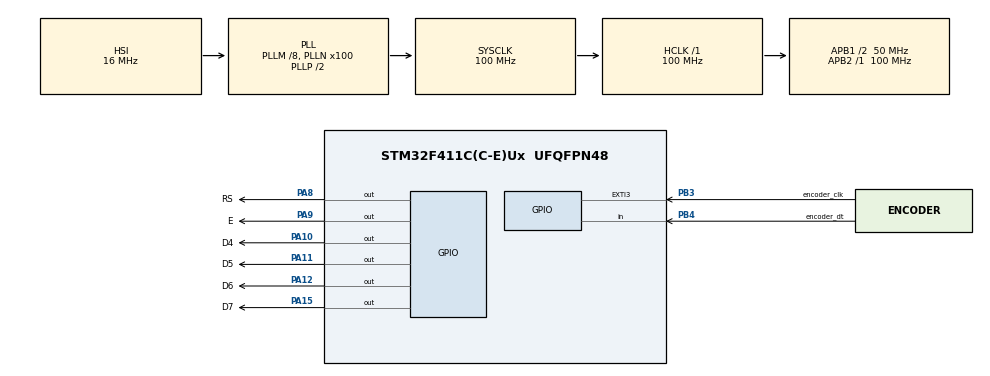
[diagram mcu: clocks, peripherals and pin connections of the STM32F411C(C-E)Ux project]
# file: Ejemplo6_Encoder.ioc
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Mcu.Family=STM32F4
Mcu.Name=STM32F411C(C-E)Ux
Mcu.Package=UFQFPN48
NVIC.EXTI3_IRQn=true\:0\:0\:false\:false\:true\:true\:true\:true
NVIC.PriorityGroup=NVIC_PRIORITYGROUP_4
PA10.GPIO_Label=D4
PA10.Signal=GPIO_Output
PA11.GPIO_Label=D5
PA11.Signal=GPIO_Output
PA12.GPIO_Label=D6
PA12.Signal=GPIO_Output
PA13.Mode=Serial_Wire
PA13.Signal=SYS_JTMS-SWDIO
PA14.Mode=Serial_Wire
PA14.Signal=SYS_JTCK-SWCLK
PA15.GPIO_Label=D7
PA15.Signal=GPIO_Output
PA8.GPIO_Label=RS
PA8.Signal=GPIO_Output
PA9.GPIO_Label=E
PA9.Signal=GPIO_Output
PB3.GPIO_Label=encoder_clk
PB3.GPIO_ModeDefaultEXTI=GPIO_MODE_IT_RISING_FALLING
PB3.Signal=GPXTI3
PB4.GPIO_Label=encoder_dt
PB4.Signal=GPIO_Input
ProjectManager.HeapSize=0x200
ProjectManager.StackSize=0x400
ProjectManager.TargetToolchain=STM32CubeIDE
RCC.48MHZClocksFreq_Value=50000000
RCC.AHBFreq_Value=100000000
RCC.APB1CLKDivider=RCC_HCLK_DIV2
RCC.APB1Freq_Value=50000000
RCC.APB1TimFreq_Value=100000000
RCC.APB2Freq_Value=100000000
RCC.APB2TimFreq_Value=100000000
RCC.CortexFreq_Value=100000000
RCC.HCLKFreq_Value=100000000
RCC.HSE_VALUE=25000000
RCC.HSI_VALUE=16000000
RCC.LSE_VALUE=32768
RCC.PLLM=8
RCC.PLLN=100
RCC.SYSCLKFreq_VALUE=100000000
RCC.SYSCLKSource=RCC_SYSCLKSOURCE_PLLCLK
RCC.VCOOutputFreq_Value=200000000
board=custom

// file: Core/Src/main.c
/* USER CODE BEGIN Header */
/**
  ******************************************************************************
  * @file           : main.c
  * @brief          : Main program body
  ******************************************************************************
  * @attention
  *
  * Copyright (c) 2023 STMicroelectronics.
  * All rights reserved.
  *
  * This software is licensed under terms that can be found in the LICENSE file
  * in the root directory of this software component.
  * If no LICENSE file comes with this software, it is provided AS-IS.
  *
  ******************************************************************************
  */
/* USER CODE END Header */
#include "main.h"

/* USER CODE BEGIN Includes */
#include "LCD_STM32.h"
#include <stdio.h>
/* USER CODE END Includes */

void SystemClock_Config(void);
static void MX_GPIO_Init(void);

/* USER CODE BEGIN 0 */
extern volatile uint16_t contador_posicion;
char stri_contador[10];
/* USER CODE END 0 */

int main(void)
{

  /* MCU Configuration--------------------------------------------------------*/

  /* Reset of all peripherals, Initializes the Flash interface and the Systick. */
  HAL_Init();

  /* Configure the system clock */
  SystemClock_Config();

  /* Initialize all configured peripherals */
  MX_GPIO_Init();
  /* USER CODE BEGIN 2 */
  LCD_STM32_Init();
  LCD_STM32_Set_Cuzrsor(0, Fila1);
  LCD_STM32_Print_String("Val. Encoder:");

  /* USER CODE END 2 */

  /* Infinite loop */
  /* USER CODE BEGIN WHILE */
  while (1)
  {
	  sprintf(stri_contador,"%04u",contador_posicion);
	  LCD_STM32_Set_Cuzrsor(0, Fila2);
	  LCD_STM32_Print_String(stri_contador);
	  HAL_Delay(500);
    /* USER CODE END WHILE */

  }
}

void SystemClock_Config(void)
{
  RCC_OscInitTypeDef RCC_OscInitStruct = {0};
  RCC_ClkInitTypeDef RCC_ClkInitStruct = {0};

  /** Configure the main internal regulator output voltage
  */
  __HAL_RCC_PWR_CLK_ENABLE();
  __HAL_PWR_VOLTAGESCALING_CONFIG(PWR_REGULATOR_VOLTAGE_SCALE1);

  /** Initializes the RCC Oscillators according to the specified parameters
  * in the RCC_OscInitTypeDef structure.
  */
  RCC_OscInitStruct.OscillatorType = RCC_OSCILLATORTYPE_HSI;
  RCC_OscInitStruct.HSIState = RCC_HSI_ON;
  RCC_OscInitStruct.HSICalibrationValue = RCC_HSICALIBRATION_DEFAULT;
  RCC_OscInitStruct.PLL.PLLState = RCC_PLL_ON;
  RCC_OscInitStruct.PLL.PLLSource = RCC_PLLSOURCE_HSI;
  RCC_OscInitStruct.PLL.PLLM = 8;
  RCC_OscInitStruct.PLL.PLLN = 100;
  RCC_OscInitStruct.PLL.PLLP = RCC_PLLP_DIV2;
  RCC_OscInitStruct.PLL.PLLQ = 4;
  if (HAL_RCC_OscConfig(&RCC_OscInitStruct) != HAL_OK)
  {
    Error_Handler();
  }

  /** Initializes the CPU, AHB and APB buses clocks
  */
  RCC_ClkInitStruct.ClockType = RCC_CLOCKTYPE_HCLK|RCC_CLOCKTYPE_SYSCLK
                              |RCC_CLOCKTYPE_PCLK1|RCC_CLOCKTYPE_PCLK2;
  RCC_ClkInitStruct.SYSCLKSource = RCC_SYSCLKSOURCE_PLLCLK;
  RCC_ClkInitStruct.AHBCLKDivider = RCC_SYSCLK_DIV1;
  RCC_ClkInitStruct.APB1CLKDivider = RCC_HCLK_DIV2;
  RCC_ClkInitStruct.APB2CLKDivider = RCC_HCLK_DIV1;

  if (HAL_RCC_ClockConfig(&RCC_ClkInitStruct, FLASH_LATENCY_3) != HAL_OK)
  {
    Error_Handler();
  }
}

static void MX_GPIO_Init(void)
{
  GPIO_InitTypeDef GPIO_InitStruct = {0};

  /* GPIO Ports Clock Enable */
  __HAL_RCC_GPIOA_CLK_ENABLE();
  __HAL_RCC_GPIOB_CLK_ENABLE();

  /*Configure GPIO pin Output Level */
  HAL_GPIO_WritePin(GPIOA, RS_Pin|E_Pin|D4_Pin|D5_Pin
                          |D6_Pin|D7_Pin, GPIO_PIN_RESET);

  /*Configure GPIO pins : RS_Pin E_Pin D4_Pin D5_Pin
                           D6_Pin D7_Pin */
  GPIO_InitStruct.Pin = RS_Pin|E_Pin|D4_Pin|D5_Pin
                          |D6_Pin|D7_Pin;
  GPIO_InitStruct.Mode = GPIO_MODE_OUTPUT_PP;
  GPIO_InitStruct.Pull = GPIO_NOPULL;
  GPIO_InitStruct.Speed = GPIO_SPEED_FREQ_LOW;
  HAL_GPIO_Init(GPIOA, &GPIO_InitStruct);

  /*Configure GPIO pin : encoder_clk_Pin */
  GPIO_InitStruct.Pin = encoder_clk_Pin;
  GPIO_InitStruct.Mode = GPIO_MODE_IT_RISING_FALLING;
  GPIO_InitStruct.Pull = GPIO_NOPULL;
  HAL_GPIO_Init(encoder_clk_GPIO_Port, &GPIO_InitStruct);

  /*Configure GPIO pin : encoder_dt_Pin */
  GPIO_InitStruct.Pin = encoder_dt_Pin;
  GPIO_InitStruct.Mode = GPIO_MODE_INPUT;
  GPIO_InitStruct.Pull = GPIO_NOPULL;
  HAL_GPIO_Init(encoder_dt_GPIO_Port, &GPIO_InitStruct);

  /* EXTI interrupt init*/
  HAL_NVIC_SetPriority(EXTI3_IRQn, 0, 0);
  HAL_NVIC_EnableIRQ(EXTI3_IRQn);

}

void Error_Handler(void)
{
  __disable_irq();
  while (1)
  {
  }
}
